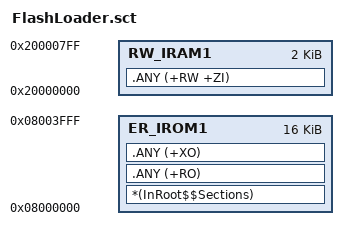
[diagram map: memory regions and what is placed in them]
; *************************************************************
; * Scatter File for MM32G0001 FLM
; * No RESET section required (no startup file)
; *************************************************************

LR_IROM1 0x08000000 0x00004000  {    ; load region size_region
  ER_IROM1 0x08000000 0x00004000  {  ; load address = execution address
   *(InRoot$$Sections)
   .ANY (+RO)
   .ANY (+XO)
  }
  RW_IRAM1 0x20000000 0x00000800  {  ; RW data
   .ANY (+RW +ZI)
  }
}
